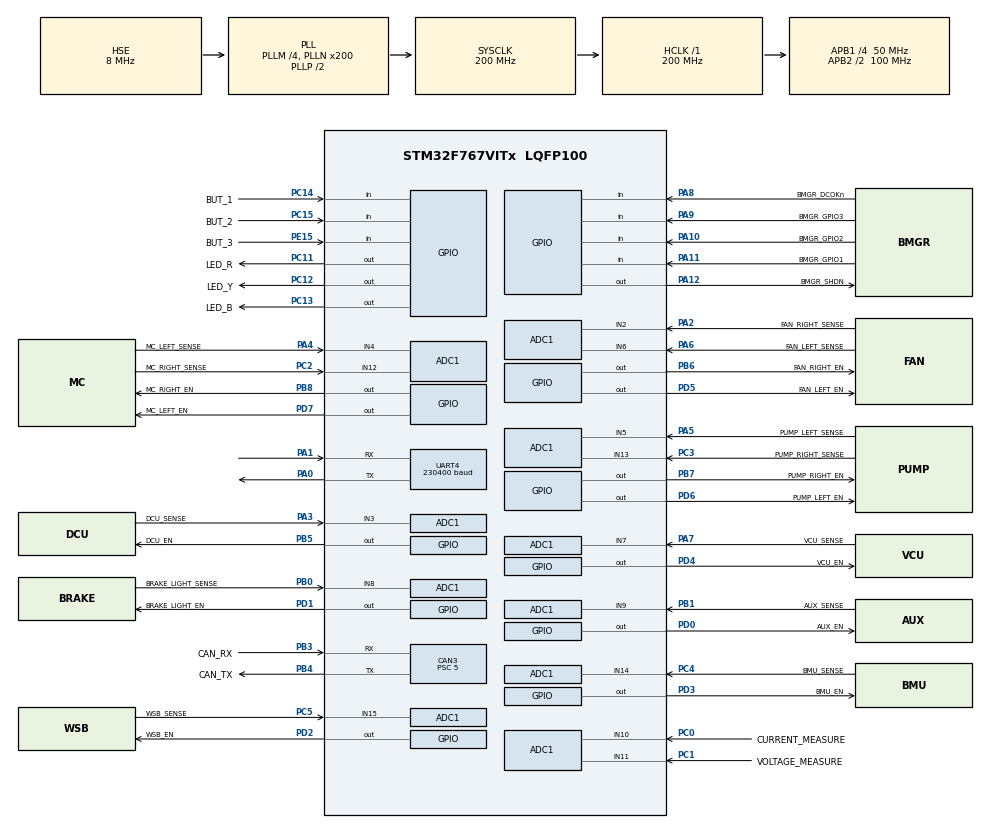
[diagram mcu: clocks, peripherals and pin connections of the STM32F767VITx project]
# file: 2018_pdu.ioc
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ADC1.Channel-0\#ChannelRegularConversion=ADC_CHANNEL_2
ADC1.Channel-1\#ChannelRegularConversion=ADC_CHANNEL_3
ADC1.Channel-10\#ChannelRegularConversion=ADC_CHANNEL_12
ADC1.Channel-11\#ChannelRegularConversion=ADC_CHANNEL_13
ADC1.Channel-12\#ChannelRegularConversion=ADC_CHANNEL_14
ADC1.Channel-13\#ChannelRegularConversion=ADC_CHANNEL_15
ADC1.Channel-2\#ChannelRegularConversion=ADC_CHANNEL_4
ADC1.Channel-3\#ChannelRegularConversion=ADC_CHANNEL_5
ADC1.Channel-4\#ChannelRegularConversion=ADC_CHANNEL_6
ADC1.Channel-5\#ChannelRegularConversion=ADC_CHANNEL_7
ADC1.Channel-6\#ChannelRegularConversion=ADC_CHANNEL_8
ADC1.Channel-7\#ChannelRegularConversion=ADC_CHANNEL_9
ADC1.Channel-8\#ChannelRegularConversion=ADC_CHANNEL_10
ADC1.Channel-9\#ChannelRegularConversion=ADC_CHANNEL_11
ADC1.ContinuousConvMode=DISABLE
ADC1.DMAContinuousRequests=ENABLE
ADC1.EOCSelection=ADC_EOC_SEQ_CONV
ADC1.EnableAnalogWatchDog=false
ADC1.ExternalTrigConv=ADC_EXTERNALTRIGCONV_T6_TRGO
ADC1.NbrOfConversion=14
ADC1.NbrOfConversionFlag=1
ADC1.Rank-0\#ChannelRegularConversion=1
ADC1.Rank-1\#ChannelRegularConversion=2
ADC1.Rank-10\#ChannelRegularConversion=11
ADC1.Rank-11\#ChannelRegularConversion=12
ADC1.Rank-12\#ChannelRegularConversion=13
ADC1.Rank-13\#ChannelRegularConversion=14
ADC1.Rank-2\#ChannelRegularConversion=3
ADC1.Rank-3\#ChannelRegularConversion=4
ADC1.Rank-4\#ChannelRegularConversion=5
ADC1.Rank-5\#ChannelRegularConversion=6
ADC1.Rank-6\#ChannelRegularConversion=7
ADC1.Rank-7\#ChannelRegularConversion=8
ADC1.Rank-8\#ChannelRegularConversion=9
ADC1.Rank-9\#ChannelRegularConversion=10
ADC1.SamplingTime-0\#ChannelRegularConversion=ADC_SAMPLETIME_84CYCLES
ADC1.SamplingTime-1\#ChannelRegularConversion=ADC_SAMPLETIME_84CYCLES
ADC1.SamplingTime-10\#ChannelRegularConversion=ADC_SAMPLETIME_84CYCLES
ADC1.SamplingTime-11\#ChannelRegularConversion=ADC_SAMPLETIME_84CYCLES
ADC1.SamplingTime-12\#ChannelRegularConversion=ADC_SAMPLETIME_84CYCLES
ADC1.SamplingTime-13\#ChannelRegularConversion=ADC_SAMPLETIME_84CYCLES
ADC1.SamplingTime-2\#ChannelRegularConversion=ADC_SAMPLETIME_84CYCLES
ADC1.SamplingTime-3\#ChannelRegularConversion=ADC_SAMPLETIME_84CYCLES
ADC1.SamplingTime-4\#ChannelRegularConversion=ADC_SAMPLETIME_84CYCLES
ADC1.SamplingTime-5\#ChannelRegularConversion=ADC_SAMPLETIME_84CYCLES
ADC1.SamplingTime-6\#ChannelRegularConversion=ADC_SAMPLETIME_84CYCLES
ADC1.SamplingTime-7\#ChannelRegularConversion=ADC_SAMPLETIME_84CYCLES
ADC1.SamplingTime-8\#ChannelRegularConversion=ADC_SAMPLETIME_84CYCLES
ADC1.SamplingTime-9\#ChannelRegularConversion=ADC_SAMPLETIME_84CYCLES
ADC1.ScanConvMode=ADC_SCAN_ENABLE
ADC1.master=1
CAN3.ABOM=ENABLE
CAN3.AWUM=ENABLE
CAN3.BS1=CAN_BS1_13TQ
CAN3.BS2=CAN_BS2_6TQ
CAN3.CalculateBaudRate=500000
CAN3.CalculateTimeBit=2000
CAN3.CalculateTimeQuantum=100.0
CAN3.NART=ENABLE
CAN3.Prescaler=5
CAN3.SJW=CAN_SJW_4TQ
Dma.ADC1.0.Direction=DMA_PERIPH_TO_MEMORY
Dma.ADC1.0.FIFOMode=DMA_FIFOMODE_DISABLE
Dma.ADC1.0.Instance=DMA2_Stream0
Dma.ADC1.0.MemDataAlignment=DMA_MDATAALIGN_WORD
Dma.ADC1.0.MemInc=DMA_MINC_ENABLE
Dma.ADC1.0.Mode=DMA_CIRCULAR
Dma.ADC1.0.PeriphDataAlignment=DMA_PDATAALIGN_WORD
Dma.ADC1.0.PeriphInc=DMA_PINC_DISABLE
Dma.ADC1.0.Priority=DMA_PRIORITY_MEDIUM
Dma.Request0=ADC1
Dma.Request1=UART4_RX
Dma.UART4_RX.1.Direction=DMA_PERIPH_TO_MEMORY
Dma.UART4_RX.1.FIFOMode=DMA_FIFOMODE_DISABLE
Dma.UART4_RX.1.Instance=DMA1_Stream2
Dma.UART4_RX.1.MemDataAlignment=DMA_MDATAALIGN_BYTE
Dma.UART4_RX.1.MemInc=DMA_MINC_ENABLE
Dma.UART4_RX.1.Mode=DMA_CIRCULAR
Dma.UART4_RX.1.PeriphDataAlignment=DMA_PDATAALIGN_BYTE
Dma.UART4_RX.1.PeriphInc=DMA_PINC_DISABLE
.UART4_RX.1.Priority=DMA_PRIORITY_LOW
FREERTOS.INCLUDE_vTaskDelayUntil=1
FREERTOS.Tasks01=mainTask,0,1000,mainTaskFunction,As weak,NULL,Dynamic,NULL,NULL;mainControl,3,1000,mainControlTask,As external,NULL,Dynamic,NULL,NULL;motorControl,2,1000,motorControlTask,As external,NULL,Dynamic,NULL,NULL;coolingControl,2,1000,coolingControlTask,As external,NULL,Dynamic,NULL,NULL;printTaskName,-2,1000,printTask,As external,NULL,Dynamic,NULL,NULL;cli,-2,1000,cliTask,As external,NULL,Dynamic,NULL,NULL;Sensor,2,1000,sensorTask,As external,NULL,Dynamic,NULL,NULL;watchdogTaskNam,3,1000,watchdogTask,As external,NULL,Dynamic,NULL,NULL;power,2,1000,powerTask,As external,NULL,Dynamic,NULL,NULL;canSendTask,3,1000,canTask,As external,NULL,Dynamic,NULL,NULL;canPublish,-2,1000,canPublishTask,As external,NULL,Dynamic,NULL,NULL
FREERTOS.configCHECK_FOR_STACK_OVERFLOW=2
FREERTOS.configGENERATE_RUN_TIME_STATS=1
FREERTOS.configTIMER_QUEUE_LENGTH=4
FREERTOS.configTIMER_TASK_PRIORITY=6
FREERTOS.configTIMER_TASK_STACK_DEPTH=1000
FREERTOS.configTOTAL_HEAP_SIZE=262144
FREERTOS.configUSE_COUNTING_SEMAPHORES=1
FREERTOS.configUSE_MALLOC_FAILED_HOOK=0
FREERTOS.configUSE_STATS_FORMATTING_FUNCTIONS=1
FREERTOS.configUSE_TIMERS=1
FREERTOS.configUSE_TRACE_FACILITY=1
IWDG.Reload=160
Mcu.Family=STM32F7
Mcu.Name=STM32F767VITx
Mcu.Package=LQFP100
NVIC.ADC_IRQn=true\:5\:0\:false\:false\:true\:true\:true\:true\:true
NVIC.CAN3_RX0_IRQn=true\:5\:0\:false\:false\:true\:true\:true\:true\:true
NVIC.CAN3_RX1_IRQn=true\:5\:0\:false\:false\:true\:true\:true\:true\:true
NVIC.CAN3_SCE_IRQn=true\:5\:0\:false\:false\:true\:true\:true\:true\:true
NVIC.CAN3_TX_IRQn=true\:5\:0\:false\:false\:true\:true\:true\:true\:true
NVIC.DMA1_Stream2_IRQn=true\:5\:0\:false\:false\:true\:true\:false\:true\:true
NVIC.DMA2_Stream0_IRQn=true\:5\:0\:false\:false\:true\:true\:false\:true\:true
NVIC.PriorityGroup=NVIC_PRIORITYGROUP_4
NVIC.TIM2_IRQn=true\:0\:0\:false\:false\:true\:false\:false\:true\:true
NVIC.TimeBase=TIM2_IRQn
NVIC.TimeBaseIP=TIM2
NVIC.UART4_IRQn=true\:5\:0\:false\:false\:true\:true\:true\:true\:true
PA0/WKUP.Mode=Asynchronous
PA0/WKUP.Signal=UART4_TX
PA1.Mode=Asynchronous
PA1.Signal=UART4_RX
PA10.GPIO_Label=BMGR_GPIO2
PA10.GPIO_PuPd=GPIO_PULLUP
PA10.Signal=GPIO_Input
PA11.GPIO_Label=BMGR_GPIO1
PA11.GPIO_PuPd=GPIO_PULLUP
PA11.Signal=GPIO_Input
PA12.GPIO_Label=BMGR_SHDN
PA12.Signal=GPIO_Output
PA13.GPIO_Label=SWDIO
PA13.Mode=Serial_Wire
PA13.Signal=SYS_JTMS-SWDIO
PA14.GPIO_Label=SWCLK
PA14.Mode=Serial_Wire
PA14.Signal=SYS_JTCK-SWCLK
PA2.GPIO_Label=FAN_RIGHT_SENSE
PA2.Signal=ADCx_IN2
PA3.GPIO_Label=DCU_SENSE
PA3.Signal=ADCx_IN3
PA4.GPIO_Label=MC_LEFT_SENSE
PA4.Signal=ADCx_IN4
PA5.GPIO_Label=PUMP_LEFT_SENSE
PA5.Signal=ADCx_IN5
PA6.GPIO_Label=FAN_LEFT_SENSE
PA6.Signal=ADCx_IN6
PA7.GPIO_Label=VCU_SENSE
PA7.Signal=ADCx_IN7
PA8.GPIO_Label=BMGR_DCOKn
PA8.GPIO_PuPd=GPIO_PULLUP
PA8.Signal=GPIO_Input
PA9.GPIO_Label=BMGR_GPIO3
PA9.GPIO_PuPd=GPIO_PULLUP
PA9.Signal=GPIO_Input
PB0.GPIO_Label=BRAKE_LIGHT_SENSE
PB0.Signal=ADCx_IN8
PB1.GPIO_Label=AUX_SENSE
PB1.Signal=ADCx_IN9
PB10.Signal=I2C2_SCL
PB11.Signal=I2C2_SDA
PB3.GPIO_Label=CAN_RX
PB3.Mode=CAN_Activate
PB3.Signal=CAN3_RX
PB4.GPIO_Label=CAN_TX
PB4.Mode=CAN_Activate
PB4.Signal=CAN3_TX
PB5.GPIO_Label=DCU_EN
PB5.Signal=GPIO_Output
PB6.GPIO_Label=FAN_RIGHT_EN
PB6.Signal=GPIO_Output
PB7.GPIO_Label=PUMP_RIGHT_EN
PB7.Signal=GPIO_Output
PB8.GPIO_Label=MC_RIGHT_EN
PB8.Signal=GPIO_Output
PC0.GPIO_Label=CURRENT_MEASURE
PC0.Signal=ADCx_IN10
PC1.GPIO_Label=VOLTAGE_MEASURE
PC1.Signal=ADCx_IN11
PC11.GPIO_Label=LED_R
PC11.Signal=GPIO_Output
PC12.GPIO_Label=LED_Y
PC12.Signal=GPIO_Output
PC13.GPIO_Label=LED_B
PC13.Signal=GPIO_Output
PC14/OSC32_IN.GPIO_Label=BUT_1
PC14/OSC32_IN.Signal=GPIO_Input
PC15/OSC32_OUT.GPIO_Label=BUT_2
PC15/OSC32_OUT.Signal=GPIO_Input
PC2.GPIO_Label=MC_RIGHT_SENSE
PC2.Signal=ADCx_IN12
PC3.GPIO_Label=PUMP_RIGHT_SENSE
PC3.Signal=ADCx_IN13
PC4.GPIO_Label=BMU_SENSE
PC4.Signal=ADCx_IN14
PC5.GPIO_Label=WSB_SENSE
PC5.Signal=ADCx_IN15
PD0.GPIO_Label=AUX_EN
PD0.Signal=GPIO_Output
PD1.GPIO_Label=BRAKE_LIGHT_EN
PD1.Signal=GPIO_Output
PD2.GPIO_Label=WSB_EN
PD2.Signal=GPIO_Output
PD3.GPIO_Label=BMU_EN
PD3.Signal=GPIO_Output
PD4.GPIO_Label=VCU_EN
PD4.Signal=GPIO_Output
PD5.GPIO_Label=FAN_LEFT_EN
PD5.Signal=GPIO_Output
PD6.GPIO_Label=PUMP_LEFT_EN
PD6.Signal=GPIO_Output
PD7.GPIO_Label=MC_LEFT_EN
PD7.Signal=GPIO_Output
PE15.GPIO_Label=BUT_3
PE15.Signal=GPIO_Input
PH0/OSC_IN.Mode=HSE-External-Oscillator
PH0/OSC_IN.Signal=RCC_OSC_IN
PH1/OSC_OUT.Mode=HSE-External-Oscillator
PH1/OSC_OUT.Signal=RCC_OSC_OUT
ProjectManager.HeapSize=0x200
ProjectManager.StackSize=0x400
ProjectManager.TargetToolchain=Makefile
RCC.AHBFreq_Value=200000000
RCC.APB1CLKDivider=RCC_HCLK_DIV4
RCC.APB1Freq_Value=50000000
RCC.APB1TimFreq_Value=100000000
RCC.APB2CLKDivider=RCC_HCLK_DIV2
RCC.APB2Freq_Value=100000000
RCC.APB2TimFreq_Value=200000000
RCC.CortexFreq_Value=200000000
RCC.HCLKFreq_Value=200000000
RCC.HSE_VALUE=8000000
RCC.HSI_VALUE=16000000
RCC.LSE_VALUE=32768
RCC.PLLM=4
RCC.PLLN=200
RCC.PLLSourceVirtual=RCC_PLLSOURCE_HSE
RCC.SYSCLKFreq_VALUE=200000000
RCC.SYSCLKSource=RCC_SYSCLKSOURCE_PLLCLK
RCC.USBFreq_Value=200000000
RCC.VCOOutputFreq_Value=400000000
SH.ADCx_IN10.0=ADC1_IN10,IN10
SH.ADCx_IN11.0=ADC1_IN11,IN11
SH.ADCx_IN12.0=ADC1_IN12,IN12
SH.ADCx_IN13.0=ADC1_IN13,IN13
SH.ADCx_IN14.0=ADC1_IN14,IN14
SH.ADCx_IN15.0=ADC1_IN15,IN15
SH.ADCx_IN2.0=ADC1_IN2,IN2
SH.ADCx_IN3.0=ADC1_IN3,IN3
SH.ADCx_IN4.0=ADC1_IN4,IN4
SH.ADCx_IN5.0=ADC1_IN5,IN5
SH.ADCx_IN6.0=ADC1_IN6,IN6
SH.ADCx_IN7.0=ADC1_IN7,IN7
SH.ADCx_IN8.0=ADC1_IN8,IN8
SH.ADCx_IN9.0=ADC1_IN9,IN9
TIM3.Period=65535
TIM6.AutoReloadPreload=TIM_AUTORELOAD_PRELOAD_ENABLE
TIM6.Period=100
TIM6.Prescaler=9999
TIM6.TIM_MasterOutputTrigger=TIM_TRGO_UPDATE
UART4.BaudRate=230400
VP_FREERTOS_VS_CMSIS_V1.Mode=CMSIS_V1
VP_IWDG_VS_IWDG.Mode=IWDG_Activate
VP_SYS_VS_tim2.Mode=TIM2
VP_TIM3_VS_ClockSourceINT.Mode=Internal
VP_TIM6_VS_ClockSourceINT.Mode=Enable_Timer
board=custom

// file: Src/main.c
/* USER CODE BEGIN Header */
/**
  ******************************************************************************
  * @file           : main.c
  * @brief          : Main program body
  ******************************************************************************
  * This notice applies to any and all portions of this file
  * that are not between comment pairs USER CODE BEGIN and
  * USER CODE END. Other portions of this file, whether
  * inserted by the user or by software development tools
  * are owned by their respective copyright owners.
  *
  * Copyright (c) 2018 STMicroelectronics International N.V.
  * All rights reserved.
  *
  * Redistribution and use in source and binary forms, with or without
  * modification, are permitted, provided that the following conditions are met:
  *
  * 1. Redistribution of source code must retain the above copyright notice,
  *    this list of conditions and the following disclaimer.
  * 2. Redistributions in binary form must reproduce the above copyright notice,
  *    this list of conditions and the following disclaimer in the documentation
  *    and/or other materials provided with the distribution.
  * 3. Neither the name of STMicroelectronics nor the names of other
  *    contributors to this software may be used to endorse or promote products
  *    derived from this software without specific written permission.
  * 4. This software, including modifications and/or derivative works of this
  *    software, must execute solely and exclusively on microcontroller or
  *    microprocessor devices manufactured by or for STMicroelectronics.
  * 5. Redistribution and use of this software other than as permitted under
  *    this license is void and will automatically terminate your rights under
  *    this license.
  *
  * THIS SOFTWARE IS PROVIDED BY STMICROELECTRONICS AND CONTRIBUTORS "AS IS"
  * AND ANY EXPRESS, IMPLIED OR STATUTORY WARRANTIES, INCLUDING, BUT NOT
  * LIMITED TO, THE IMPLIED WARRANTIES OF MERCHANTABILITY, FITNESS FOR A
  * PARTICULAR PURPOSE AND NON-INFRINGEMENT OF THIRD PARTY INTELLECTUAL PROPERTY
  * RIGHTS ARE DISCLAIMED TO THE FULLEST EXTENT PERMITTED BY LAW. IN NO EVENT
  * SHALL STMICROELECTRONICS OR CONTRIBUTORS BE LIABLE FOR ANY DIRECT, INDIRECT,
  * INCIDENTAL, SPECIAL, EXEMPLARY, OR CONSEQUENTIAL DAMAGES (INCLUDING, BUT NOT
  * LIMITED TO, PROCUREMENT OF SUBSTITUTE GOODS OR SERVICES; LOSS OF USE, DATA,
  * OR PROFITS; OR BUSINESS INTERRUPTION) HOWEVER CAUSED AND ON ANY THEORY OF
  * LIABILITY, WHETHER IN CONTRACT, STRICT LIABILITY, OR TORT (INCLUDING
  * NEGLIGENCE OR OTHERWISE) ARISING IN ANY WAY OUT OF THE USE OF THIS SOFTWARE,
  * EVEN IF ADVISED OF THE POSSIBILITY OF SUCH DAMAGE.
  *
  ******************************************************************************
  */
/* USER CODE END Header */
#include "main.h"
#include "cmsis_os.h"
#include "adc.h"
#include "can.h"
#include "dma.h"
#include "iwdg.h"
#include "tim.h"
#include "usart.h"
#include "gpio.h"

/* USER CODE BEGIN Includes */
#include "stdio.h"
#include "generalErrorHandler.h"
#include "watchdog.h"
#include "stm32f7xx_hal_timebase_tim.c"
#include "errorHandler.h"
/* USER CODE END Includes */

void SystemClock_Config(void);
void MX_FREERTOS_Init(void);
/* USER CODE BEGIN PFP */
/* Private function prototypes -----------------------------------------------*/
__weak void userInit() {}
/* USER CODE END PFP */

int main(void)
{
  /* USER CODE BEGIN 1 */
  checkForWDReset();
  /* USER CODE END 1 */

  /* MCU Configuration--------------------------------------------------------*/

  /* Reset of all peripherals, Initializes the Flash interface and the Systick. */
  HAL_Init();

  /* Configure the system clock */
  SystemClock_Config();

  /* Initialize all configured peripherals */
  MX_GPIO_Init();
  MX_DMA_Init();
  MX_ADC1_Init();
  MX_CAN3_Init();
  MX_UART4_Init();
  MX_TIM3_Init();
  MX_IWDG_Init();
  MX_TIM6_Init();
  /* USER CODE BEGIN 2 */
  userInit();
  printWDResetState();
  handleWatchdogReset();
  /* USER CODE END 2 */

  /* Call init function for freertos objects (in freertos.c) */
  MX_FREERTOS_Init();
  /* Start scheduler */
  osKernelStart();

  /* We should never get here as control is now taken by the scheduler */
  /* Infinite loop */
  while (1)
  {

  }
}

void SystemClock_Config(void)
{
  RCC_OscInitTypeDef RCC_OscInitStruct = {0};
  RCC_ClkInitTypeDef RCC_ClkInitStruct = {0};
  RCC_PeriphCLKInitTypeDef PeriphClkInitStruct = {0};

  /** Configure the main internal regulator output voltage
  */
  __HAL_RCC_PWR_CLK_ENABLE();
  __HAL_PWR_VOLTAGESCALING_CONFIG(PWR_REGULATOR_VOLTAGE_SCALE1);
  /** Initializes the RCC Oscillators according to the specified parameters
  * in the RCC_OscInitTypeDef structure.
  */
  RCC_OscInitStruct.OscillatorType = RCC_OSCILLATORTYPE_LSI|RCC_OSCILLATORTYPE_HSE;
  RCC_OscInitStruct.HSEState = RCC_HSE_ON;
  RCC_OscInitStruct.LSIState = RCC_LSI_ON;
  RCC_OscInitStruct.PLL.PLLState = RCC_PLL_ON;
  RCC_OscInitStruct.PLL.PLLSource = RCC_PLLSOURCE_HSE;
  RCC_OscInitStruct.PLL.PLLM = 4;
  RCC_OscInitStruct.PLL.PLLN = 200;
  RCC_OscInitStruct.PLL.PLLP = RCC_PLLP_DIV2;
  RCC_OscInitStruct.PLL.PLLQ = 2;
  RCC_OscInitStruct.PLL.PLLR = 2;
  if (HAL_RCC_OscConfig(&RCC_OscInitStruct) != HAL_OK)
  {
    PDU_error(Failure_RCC_OscConfig);
  }
  /** Activate the Over-Drive mode
  */
  if (HAL_PWREx_EnableOverDrive() != HAL_OK)
  {
    PDU_error(Failure_PWREx_EnableOverDrive);
  }
  /** Initializes the CPU, AHB and APB buses clocks
  */
  RCC_ClkInitStruct.ClockType = RCC_CLOCKTYPE_HCLK|RCC_CLOCKTYPE_SYSCLK
                              |RCC_CLOCKTYPE_PCLK1|RCC_CLOCKTYPE_PCLK2;
  RCC_ClkInitStruct.SYSCLKSource = RCC_SYSCLKSOURCE_PLLCLK;
  RCC_ClkInitStruct.AHBCLKDivider = RCC_SYSCLK_DIV1;
  RCC_ClkInitStruct.APB1CLKDivider = RCC_HCLK_DIV4;
  RCC_ClkInitStruct.APB2CLKDivider = RCC_HCLK_DIV2;

  if (HAL_RCC_ClockConfig(&RCC_ClkInitStruct, FLASH_LATENCY_6) != HAL_OK)
  {
    PDU_error(Failure_RCC_ClockConfig);
  }
  PeriphClkInitStruct.PeriphClockSelection = RCC_PERIPHCLK_UART4;
  PeriphClkInitStruct.Uart4ClockSelection = RCC_UART4CLKSOURCE_PCLK1;
  if (HAL_RCCEx_PeriphCLKConfig(&PeriphClkInitStruct) != HAL_OK)
  {
    PDU_error(Failure_RCCEx_PeriphCLKConfig);
  }
}

void HAL_TIM_PeriodElapsedCallback(TIM_HandleTypeDef *htim)
{
  if (htim->Instance == TIM2) {
    HAL_IncTick();
  }
}

void Error_Handler(void)
{
  /* USER CODE BEGIN Error_Handler_Debug */
  /* User can add his own implementation to report the HAL error return state */
  _handleError(__FILE__, __LINE__);
  /* USER CODE END Error_Handler_Debug */
}

#ifdef  USE_FULL_ASSERT
/**
  * @brief  Reports the name of the source file and the source line number
  *         where the assert_param error has occurred.
  * @param  file: pointer to the source file name
  * @param  line: assert_param error line source number
  * @retval None
  */
void assert_failed(uint8_t *file, uint32_t line)
{
  /* USER CODE BEGIN 6 */
  /* User can add his own implementation to report the file name and line number,
     tex: printf("Wrong parameters value: file %s on line %d\r\n", file, line) */
  printf("Wrong parameters value: file %s on line %ld\r\n", file, line);
  /* USER CODE END 6 */
}
#endif /* USE_FULL_ASSERT */

/************************ (C) COPYRIGHT STMicroelectronics *****END OF FILE****/

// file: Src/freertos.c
/* USER CODE BEGIN Header */
/**
  ******************************************************************************
  * File Name          : freertos.c
  * Description        : Code for freertos applications
  ******************************************************************************
  * This notice applies to any and all portions of this file
  * that are not between comment pairs USER CODE BEGIN and
  * USER CODE END. Other portions of this file, whether
  * inserted by the user or by software development tools
  * are owned by their respective copyright owners.
  *
  * Copyright (c) 2018 STMicroelectronics International N.V.
  * All rights reserved.
  *
  * Redistribution and use in source and binary forms, with or without
  * modification, are permitted, provided that the following conditions are met:
  *
  * 1. Redistribution of source code must retain the above copyright notice,
  *    this list of conditions and the following disclaimer.
  * 2. Redistributions in binary form must reproduce the above copyright notice,
  *    this list of conditions and the following disclaimer in the documentation
  *    and/or other materials provided with the distribution.
  * 3. Neither the name of STMicroelectronics nor the names of other
  *    contributors to this software may be used to endorse or promote products
  *    derived from this software without specific written permission.
  * 4. This software, including modifications and/or derivative works of this
  *    software, must execute solely and exclusively on microcontroller or
  *    microprocessor devices manufactured by or for STMicroelectronics.
  * 5. Redistribution and use of this software other than as permitted under
  *    this license is void and will automatically terminate your rights under
  *    this license.
  *
  * THIS SOFTWARE IS PROVIDED BY STMICROELECTRONICS AND CONTRIBUTORS "AS IS"
  * AND ANY EXPRESS, IMPLIED OR STATUTORY WARRANTIES, INCLUDING, BUT NOT
  * LIMITED TO, THE IMPLIED WARRANTIES OF MERCHANTABILITY, FITNESS FOR A
  * PARTICULAR PURPOSE AND NON-INFRINGEMENT OF THIRD PARTY INTELLECTUAL PROPERTY
  * RIGHTS ARE DISCLAIMED TO THE FULLEST EXTENT PERMITTED BY LAW. IN NO EVENT
  * SHALL STMICROELECTRONICS OR CONTRIBUTORS BE LIABLE FOR ANY DIRECT, INDIRECT,
  * INCIDENTAL, SPECIAL, EXEMPLARY, OR CONSEQUENTIAL DAMAGES (INCLUDING, BUT NOT
  * LIMITED TO, PROCUREMENT OF SUBSTITUTE GOODS OR SERVICES; LOSS OF USE, DATA,
  * OR PROFITS; OR BUSINESS INTERRUPTION) HOWEVER CAUSED AND ON ANY THEORY OF
  * LIABILITY, WHETHER IN CONTRACT, STRICT LIABILITY, OR TORT (INCLUDING
  * NEGLIGENCE OR OTHERWISE) ARISING IN ANY WAY OUT OF THE USE OF THIS SOFTWARE,
  * EVEN IF ADVISED OF THE POSSIBILITY OF SUCH DAMAGE.
  *
  ******************************************************************************
  */
/* USER CODE END Header */

#include "FreeRTOS.h"
#include "task.h"
#include "main.h"
#include "cmsis_os.h"

/* USER CODE BEGIN Includes */
#include "stm32f7xx_hal.h"

/* USER CODE END Includes */

osThreadId mainTaskHandle;
osThreadId mainControlHandle;
osThreadId motorControlHandle;
osThreadId coolingControlHandle;
osThreadId printTaskNameHandle;
osThreadId cliHandle;
osThreadId SensorHandle;
osThreadId watchdogTaskNamHandle;
osThreadId powerHandle;
osThreadId canSendTaskHandle;
osThreadId canPublishHandle;
osThreadId motorCoolingHandle;

void mainTaskFunction(void const * argument);
extern void mainControlTask(void const * argument);
extern void motorControlTask(void const * argument);
extern void coolingControlTask(void const * argument);
extern void printTask(void const * argument);
extern void cliTask(void const * argument);
extern void sensorTask(void const * argument);
extern void watchdogTask(void const * argument);
extern void powerTask(void const * argument);
extern void canTask(void const * argument);
extern void canPublishTask(void const * argument);
extern void motorCoolingTask(void const * argument);

void MX_FREERTOS_Init(void); /* (MISRA C 2004 rule 8.1) */

/* GetIdleTaskMemory prototype (linked to static allocation support) */
void vApplicationGetIdleTaskMemory( StaticTask_t **ppxIdleTaskTCBBuffer, StackType_t **ppxIdleTaskStackBuffer, uint32_t *pulIdleTaskStackSize );

/* GetTimerTaskMemory prototype (linked to static allocation support) */
void vApplicationGetTimerTaskMemory( StaticTask_t **ppxTimerTaskTCBBuffer, StackType_t **ppxTimerTaskStackBuffer, uint32_t *pulTimerTaskStackSize );

/* Hook prototypes */
void configureTimerForRunTimeStats(void);
unsigned long getRunTimeCounterValue(void);
void vApplicationStackOverflowHook(xTaskHandle xTask, signed char *pcTaskName);

/* USER CODE BEGIN 1 */
/* Functions needed when configGENERATE_RUN_TIME_STATS is on */
__weak void configureTimerForRunTimeStats(void)
{

}

__weak unsigned long getRunTimeCounterValue(void)
{
return 0;
}
/* USER CODE END 1 */

/* USER CODE BEGIN 4 */
__weak void vApplicationStackOverflowHook(xTaskHandle xTask, signed char *pcTaskName)
{
   /* Run time stack overflow checking is performed if
   configCHECK_FOR_STACK_OVERFLOW is defined to 1 or 2. This hook function is
   called if a stack overflow is detected. */
}
/* USER CODE END 4 */

/* USER CODE BEGIN GET_IDLE_TASK_MEMORY */
static StaticTask_t xIdleTaskTCBBuffer;
static StackType_t xIdleStack[configMINIMAL_STACK_SIZE];

void vApplicationGetIdleTaskMemory( StaticTask_t **ppxIdleTaskTCBBuffer, StackType_t **ppxIdleTaskStackBuffer, uint32_t *pulIdleTaskStackSize )
{
  *ppxIdleTaskTCBBuffer = &xIdleTaskTCBBuffer;
  *ppxIdleTaskStackBuffer = &xIdleStack[0];
  *pulIdleTaskStackSize = configMINIMAL_STACK_SIZE;
  /* place for user code */
}
/* USER CODE END GET_IDLE_TASK_MEMORY */

/* USER CODE BEGIN GET_TIMER_TASK_MEMORY */
static StaticTask_t xTimerTaskTCBBuffer;
static StackType_t xTimerStack[configTIMER_TASK_STACK_DEPTH];

void vApplicationGetTimerTaskMemory( StaticTask_t **ppxTimerTaskTCBBuffer, StackType_t **ppxTimerTaskStackBuffer, uint32_t *pulTimerTaskStackSize )
{
  *ppxTimerTaskTCBBuffer = &xTimerTaskTCBBuffer;
  *ppxTimerTaskStackBuffer = &xTimerStack[0];
  *pulTimerTaskStackSize = configTIMER_TASK_STACK_DEPTH;
  /* place for user code */
}
/* USER CODE END GET_TIMER_TASK_MEMORY */

void MX_FREERTOS_Init(void) {

  /* Create the thread(s) */
  /* definition and creation of mainTask */
  osThreadDef(mainTask, mainTaskFunction, osPriorityNormal, 0, 1000);
  mainTaskHandle = osThreadCreate(osThread(mainTask), NULL);

  /* definition and creation of mainControl */
  osThreadDef(mainControl, mainControlTask, osPriorityRealtime, 0, 1000);
  mainControlHandle = osThreadCreate(osThread(mainControl), NULL);

  /* definition and creation of motorControl */
  osThreadDef(motorControl, motorControlTask, osPriorityHigh, 0, 1000);
  motorControlHandle = osThreadCreate(osThread(motorControl), NULL);

  /* definition and creation of coolingControl */
  osThreadDef(coolingControl, coolingControlTask, osPriorityHigh, 0, 1000);
  coolingControlHandle = osThreadCreate(osThread(coolingControl), NULL);

  /* definition and creation of printTaskName */
  osThreadDef(printTaskName, printTask, osPriorityLow, 0, 1000);
  printTaskNameHandle = osThreadCreate(osThread(printTaskName), NULL);

  /* definition and creation of cli */
  osThreadDef(cli, cliTask, osPriorityLow, 0, 1000);
  cliHandle = osThreadCreate(osThread(cli), NULL);

  /* definition and creation of Sensor */
  osThreadDef(Sensor, sensorTask, osPriorityHigh, 0, 1000);
  SensorHandle = osThreadCreate(osThread(Sensor), NULL);

  /* definition and creation of watchdogTaskNam */
  osThreadDef(watchdogTaskNam, watchdogTask, osPriorityRealtime, 0, 1000);
  watchdogTaskNamHandle = osThreadCreate(osThread(watchdogTaskNam), NULL);

  /* definition and creation of power */
  osThreadDef(power, powerTask, osPriorityHigh, 0, 1000);
  powerHandle = osThreadCreate(osThread(power), NULL);

  /* definition and creation of canSendTask */
  osThreadDef(canSendTask, canTask, osPriorityRealtime, 0, 1000);
  canSendTaskHandle = osThreadCreate(osThread(canSendTask), NULL);

  /* definition and creation of canPublish */
  osThreadDef(canPublish, canPublishTask, osPriorityLow, 0, 1000);
  canPublishHandle = osThreadCreate(osThread(canPublish), NULL);

  /* definition and creation of motorCooling */
  osThreadDef(motorCooling, motorCoolingTask, osPriorityIdle, 0, 1000);
  motorCoolingHandle = osThreadCreate(osThread(motorCooling), NULL);

}

__weak void mainTaskFunction(void const * argument)
{
  for(;;)
  {
    osDelay(1);
  }
}

/************************ (C) COPYRIGHT STMicroelectronics *****END OF FILE****/
